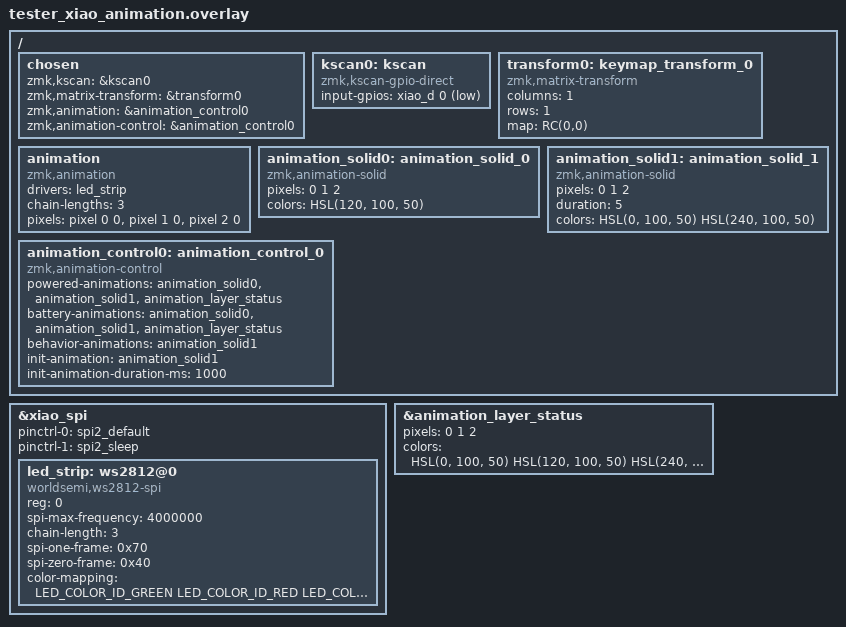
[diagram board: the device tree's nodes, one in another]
#include <dt-bindings/led/led.h>
#include <zmk_driver_animation/animation.dtsi>
#include <zmk_driver_animation/animation_layer_status.dtsi>
#include <behaviors/animation_control.dtsi>
#include <behaviors/animation_trigger.dtsi>
#include <dt-bindings/zmk_driver_animation/animation_control.h>
#include <dt-bindings/zmk/matrix_transform.h>

&xiao_spi {
    status = "okay";
    pinctrl-0 = <&spi2_default>;
    pinctrl-1 = <&spi2_sleep>;
    pinctrl-names = "default", "sleep";

    led_strip: ws2812@0 {
        compatible = "worldsemi,ws2812-spi";
        reg = <0>;
        spi-max-frequency = <4000000>;
        chain-length = <3>;
        spi-one-frame = <0x70>;
        spi-zero-frame = <0x40>;
        color-mapping = <LED_COLOR_ID_GREEN
                         LED_COLOR_ID_RED
                         LED_COLOR_ID_BLUE>;
    };
};

/ {
    chosen {
        zmk,kscan = &kscan0;
        zmk,matrix-transform = &transform0;
        /* Phase B onward: `zmk,animation` must resolve to the
         * animation-control singleton (DESIGN.md #4 item 10), and
         * `zmk,animation-control` is used internally by animations that
         * enqueue an ad-hoc overlay (battery-status's low-battery alert). */
        zmk,animation = &animation_control0;
        zmk,animation-control = &animation_control0;
    };

    kscan0: kscan {
        compatible = "zmk,kscan-gpio-direct";
        input-gpios = <&xiao_d 0 (GPIO_ACTIVE_LOW | GPIO_PULL_UP)>;
    };

    transform0: keymap_transform_0 {
        compatible = "zmk,matrix-transform";
        columns = <1>;
        rows = <1>;
        map = <RC(0,0)>;
    };

    animation: animation {
        compatible = "zmk,animation";
        drivers = <&led_strip>;
        chain-lengths = <3>;
        pixels = <&pixel 0 0>, <&pixel 1 0>, <&pixel 2 0>;
    };

    animation_solid0: animation_solid_0 {
        compatible = "zmk,animation-solid";
        pixels = <0 1 2>;
        colors = <HSL(120, 100, 50)>;
    };

    animation_solid1: animation_solid_1 {
        compatible = "zmk,animation-solid";
        pixels = <0 1 2>;
        duration = <5>;
        colors = <HSL(0, 100, 50) HSL(240, 100, 50)>;
    };

    animation_control0: animation_control_0 {
        compatible = "zmk,animation-control";
        /* At least 2 real animation types selectable per power source,
         * matching what a real keyboard would configure. */
        powered-animations = <&animation_solid0 &animation_solid1 &animation_layer_status>;
        battery-animations = <&animation_solid0 &animation_solid1 &animation_layer_status>;
        behavior-animations = <&animation_solid1>;
        init-animation = <&animation_solid1>;
        init-animation-duration-ms = <1000>;
    };
};

&animation_layer_status {
    pixels = <0 1 2>;
    colors = <HSL(0, 100, 50) HSL(120, 100, 50) HSL(240, 100, 50)>;
};
